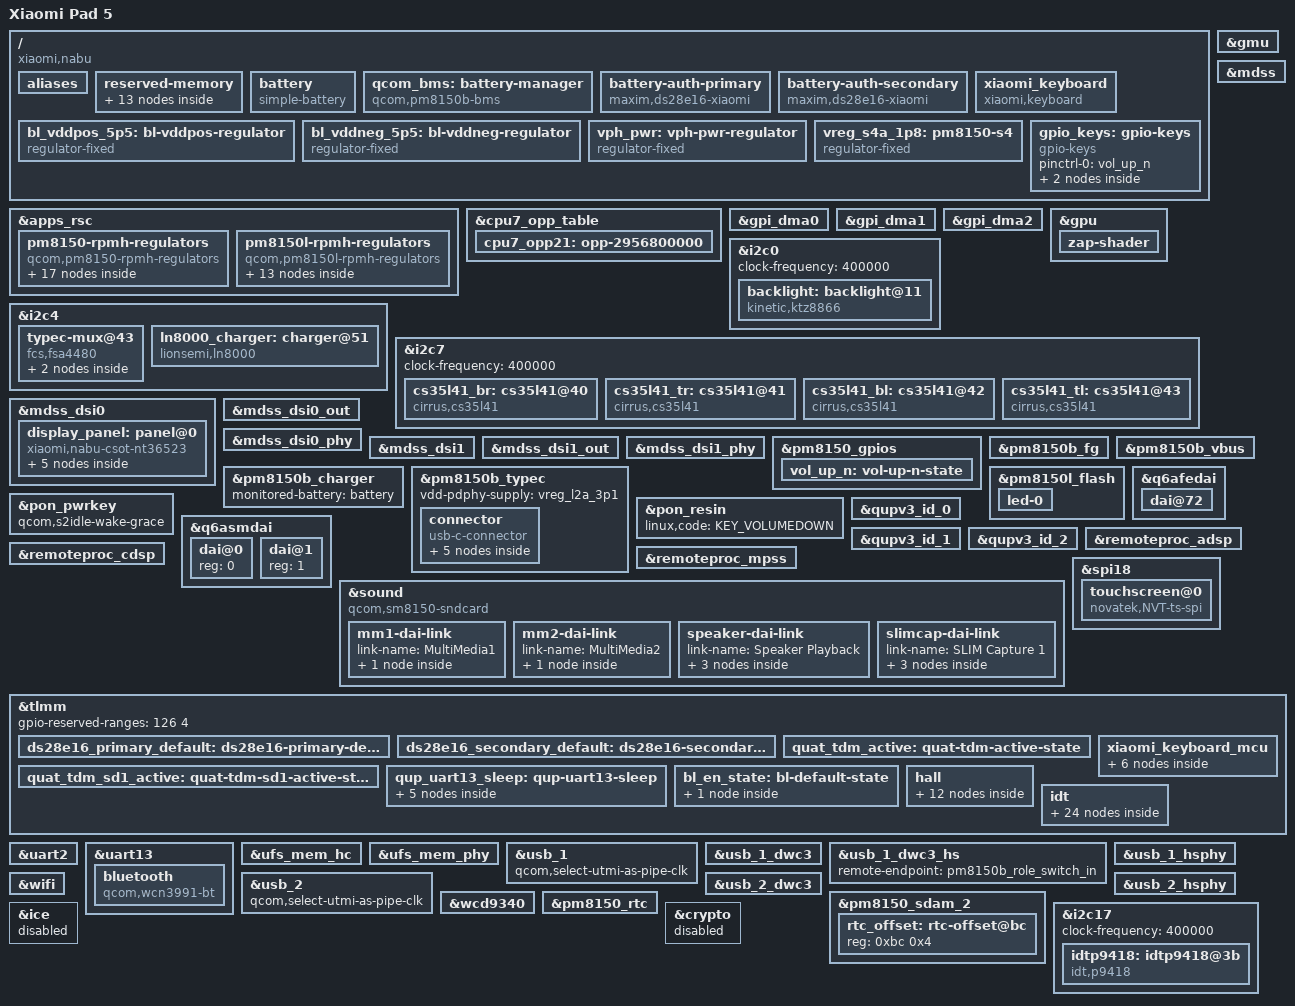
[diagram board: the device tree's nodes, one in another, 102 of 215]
// SPDX-License-Identifier: BSD-3-Clause
/*
 * Copyright (c) 2023-2024, map220v <map220v300@gmail.com>
 */

/dts-v1/;

#include <dt-bindings/arm/qcom,ids.h>
#include <dt-bindings/gpio/gpio.h>
#include <dt-bindings/leds/common.h>
#include <dt-bindings/phy/phy.h>
#include <dt-bindings/regulator/qcom,rpmh-regulator.h>
#include <dt-bindings/sound/qcom,q6asm.h>
#include <dt-bindings/usb/pd.h>
#include "sm8150.dtsi"
#include "sm8150-wcd9340.dtsi"
#include "pm8150.dtsi"
#include "pm8150b.dtsi"
#include "pm8150l.dtsi"

/delete-node/ &tz_mem;
/delete-node/ &rmtfs_mem;
/delete-node/ &adsp_mem;
/delete-node/ &mpss_mem;
/delete-node/ &venus_mem;
/delete-node/ &slpi_mem;
/delete-node/ &ipa_fw_mem;
/delete-node/ &ipa_gsi_mem;
/delete-node/ &gpu_mem;
/delete-node/ &spss_mem;
/delete-node/ &cdsp_mem;

/ {
	model = "Xiaomi Pad 5";
	compatible = "xiaomi,nabu", "qcom,sm8150";
	chassis-type = "tablet";
	qcom,msm-id = <QCOM_ID_SM8150 0x20002>; /* SM8150 v2.2 */
	qcom,board-id = <48 0>;

	aliases {
		serial0 = &uart2;
		hsuart0 = &uart13;
		wifi0 = &wifi;
	};

	reserved-memory {
		#address-cells = <2>;
		#size-cells = <2>;
		ranges;

		tz_mem: memory@86200000 {
			reg = <0x0 0x86200000 0x0 0x5500000>;
			no-map;
		};

		adsp_mem: memory@8be00000 {
			reg = <0x0 0x8be00000 0x0 0x2200000>;
			no-map;
		};

		mpss_mem: memory@8e000000 {
			reg = <0x0 0x8e000000 0x0 0x9600000>;
			no-map;
		};

		venus_mem: memory@97600000 {
			reg = <0x0 0x97600000 0x0 0x500000>;
			no-map;
		};

		slpi_mem: memory@97b00000 {
			reg = <0x0 0x97b00000 0x0 0x1400000>;
			no-map;
		};

		ipa_fw_mem: memory@98f00000 {
			reg = <0x0 0x98f00000 0x0 0x10000>;
			no-map;
		};

		ipa_gsi_mem: memory@98f10000 {
			reg = <0x0 0x98f10000 0x0 0x5000>;
			no-map;
		};

		gpu_mem: memory@98f15000 {
			reg = <0x0 0x98f15000 0x0 0x2000>;
			no-map;
		};

		spss_mem: memory@99000000 {
			reg = <0x0 0x99000000 0x0 0x100000>;
			no-map;
		};

		cdsp_mem: memory@99100000 {
			reg = <0x0 0x99100000 0x0 0x1400000>;
			no-map;
		};

		cdsp_sec_mem: memory@a8800000 {
			reg = <0x0 0xa8800000 0x0 0x3c00000>;
			no-map;
		};

		ramoops@b0000000 {
			compatible = "ramoops";
			reg = <0x0 0xb0000000 0x0 0x400000>;
			record-size = <0x1000>;
			console-size = <0x200000>;
			ecc-size = <16>;
			no-map;
		};

		rmtfs_mem: memory@fe101000 {
			compatible = "qcom,rmtfs-mem";
			reg = <0 0xfe101000 0 0x300000>;
			no-map;

			qcom,client-id = <1>;
			qcom,vmid = <15>;
		};
	};

	battery: battery {
		compatible = "simple-battery";
		charge-full-design-microamp-hours = <8720000>;
		energy-full-design-microwatt-hours = <33600000>;
		voltage-min-design-microvolt = <3400000>;
		voltage-max-design-microvolt = <4480000>;
		constant-charge-current-max-microamp = <3000000>;
		constant-charge-voltage-max-microvolt = <4480000>;
	};

	qcom_bms: battery-manager {
		compatible = "qcom,pm8150b-bms";
		qcom,required-authenticators = <3>;
		/* tcpm source psy (CC-driven attach/detach); powers direct-charge teardown */
		qcom,tcpm-psy = <&pm8150b_typec>;
		status = "okay";
	};

	battery-auth-primary {
		compatible = "maxim,ds28e16-xiaomi";
		gpios = <&tlmm 5 GPIO_ACTIVE_HIGH>;
		maxim,auth-role = "primary";
		maxim,gpio-config-address = <0x03d05000>;
		maxim,gpio-io-offset = <0x4>;
		pinctrl-names = "default";
		pinctrl-0 = <&ds28e16_primary_default>;
	};

	battery-auth-secondary {
		compatible = "maxim,ds28e16-xiaomi";
		gpios = <&tlmm 10 GPIO_ACTIVE_HIGH>;
		maxim,auth-role = "secondary";
		maxim,gpio-config-address = <0x0390a000>;
		maxim,gpio-io-offset = <0x4>;
		pinctrl-names = "default";
		pinctrl-0 = <&ds28e16_secondary_default>;
	};

	xiaomi_keyboard {
		compatible = "xiaomi,keyboard";
		pinctrl-names = "pm_kb_active", "pm_kb_suspend";
		pinctrl-0 = <&xiaomi_keyboard_active>;
		pinctrl-1 = <&xiaomi_keyboard_suspend>;
		xiaomi-keyboard,rst-gpio = <&tlmm 49 0x00>;
		xiaomi-keyboard,in-irq-gpio = <&tlmm 41 0x2001>;
		xiaomi-keyboard,vdd-gpio = <&tlmm 82 0x00>;
		status = "ok";
	};

	bl_vddpos_5p5: bl-vddpos-regulator {
		compatible = "regulator-fixed";
		regulator-name = "bl_vddpos_5p5";
		regulator-min-microvolt = <5500000>;
		regulator-max-microvolt = <5500000>;
		regulator-enable-ramp-delay = <233>;
		gpio = <&tlmm 114 GPIO_ACTIVE_HIGH>;
		enable-active-high;
		regulator-boot-on;
	};

	bl_vddneg_5p5: bl-vddneg-regulator {
		compatible = "regulator-fixed";
		regulator-name = "bl_vddneg_5p5";
		regulator-min-microvolt = <5500000>;
		regulator-max-microvolt = <5500000>;
		regulator-enable-ramp-delay = <233>;
		gpio = <&tlmm 115 GPIO_ACTIVE_HIGH>;
		enable-active-high;
		regulator-boot-on;
	};

	vph_pwr: vph-pwr-regulator {
		compatible = "regulator-fixed";
		regulator-name = "vph_pwr";
		regulator-min-microvolt = <3700000>;
		regulator-max-microvolt = <3700000>;
	};

	/*
	 * Apparently RPMh does not provide support for PM8150 S4 because it
	 * is always-on; model it as a fixed regulator.
	 */
	vreg_s4a_1p8: pm8150-s4 {
		compatible = "regulator-fixed";
		regulator-name = "vreg_s4a_1p8";

		regulator-min-microvolt = <1800000>;
		regulator-max-microvolt = <1800000>;

		regulator-always-on;
		regulator-boot-on;

		vin-supply = <&vph_pwr>;
	};

	gpio_keys: gpio-keys {
		compatible = "gpio-keys";

		pinctrl-names = "default";
		pinctrl-0 = <&vol_up_n>;

		key-vol-up {
			label = "Volume Up";
			gpios = <&pm8150_gpios 6 GPIO_ACTIVE_LOW>;
			linux,code = <KEY_VOLUMEUP>;
			debounce-interval = <15>;
			linux,can-disable;
			wakeup-source;
		};

		event-hall-sensor {
			label = "Hall Effect Sensor";
			gpios = <&tlmm 9 GPIO_ACTIVE_LOW>;
			linux,input-type = <EV_SW>;
			linux,code = <SW_LID>;
			debounce-interval = <15>;
			linux,can-disable;
			linux,notify-chain;
			wakeup-source;
		};
	};
};

&apps_rsc {
	pm8150-rpmh-regulators {
		compatible = "qcom,pm8150-rpmh-regulators";
		qcom,pmic-id = "a";

		vdd-s1-supply = <&vph_pwr>;
		vdd-s2-supply = <&vph_pwr>;
		vdd-s3-supply = <&vph_pwr>;
		vdd-s4-supply = <&vph_pwr>;
		vdd-s5-supply = <&vph_pwr>;
		vdd-s6-supply = <&vph_pwr>;
		vdd-s7-supply = <&vph_pwr>;
		vdd-s8-supply = <&vph_pwr>;
		vdd-s9-supply = <&vph_pwr>;
		vdd-s10-supply = <&vph_pwr>;

		vdd-l1-l8-l11-supply = <&vreg_s6a_0p9>;
		vdd-l2-l10-supply = <&vreg_bob>;
		vdd-l3-l4-l5-l18-supply = <&vreg_s6a_0p9>;
		vdd-l6-l9-supply = <&vreg_s8c_1p3>;
		vdd-l7-l12-l14-l15-supply = <&vreg_s5a_2p0>;
		vdd-l13-l16-l17-supply = <&vreg_bob>;

		vreg_s5a_2p0: smps5 {
			regulator-min-microvolt = <1904000>;
			regulator-max-microvolt = <2040000>;
		};

		vreg_s6a_0p9: smps6 {
			regulator-min-microvolt = <920000>;
			regulator-max-microvolt = <1128000>;
		};

		vreg_l1a_0p75: ldo1 {
			regulator-min-microvolt = <752000>;
			regulator-max-microvolt = <752000>;
			regulator-initial-mode = <RPMH_REGULATOR_MODE_HPM>;
		};

		vreg_l2a_3p1: ldo2 {
			regulator-min-microvolt = <3072000>;
			regulator-max-microvolt = <3072000>;
			regulator-initial-mode = <RPMH_REGULATOR_MODE_HPM>;
		};

		vreg_l3a_0p8: ldo3 {
			regulator-min-microvolt = <480000>;
			regulator-max-microvolt = <932000>;
			regulator-initial-mode = <RPMH_REGULATOR_MODE_HPM>;
		};

		vreg_l5a_0p8: ldo5 {
			regulator-min-microvolt = <880000>;
			regulator-max-microvolt = <880000>;
			regulator-initial-mode = <RPMH_REGULATOR_MODE_HPM>;
		};

		vreg_l6a_1p2: ldo6 {
			regulator-min-microvolt = <1200000>;
			regulator-max-microvolt = <1200000>;
			regulator-initial-mode = <RPMH_REGULATOR_MODE_HPM>;
		};

		vreg_l7a_1p8: ldo7 {
			regulator-min-microvolt = <1800000>;
			regulator-max-microvolt = <1800000>;
			regulator-initial-mode = <RPMH_REGULATOR_MODE_HPM>;
		};

		vreg_l9a_1p2: ldo9 {
			regulator-min-microvolt = <1200000>;
			regulator-max-microvolt = <1200000>;
			regulator-initial-mode = <RPMH_REGULATOR_MODE_HPM>;
		};

		vreg_l10a_2p5: ldo10 {
			regulator-min-microvolt = <2504000>;
			regulator-max-microvolt = <2950000>;
			regulator-initial-mode = <RPMH_REGULATOR_MODE_HPM>;
		};

		vreg_l11a_0p8: ldo11 {
			regulator-min-microvolt = <800000>;
			regulator-max-microvolt = <800000>;
			regulator-initial-mode = <RPMH_REGULATOR_MODE_HPM>;
		};

		vreg_l12a_1p8: ldo12 {
			regulator-min-microvolt = <1800000>;
			regulator-max-microvolt = <1800000>;
			regulator-initial-mode = <RPMH_REGULATOR_MODE_HPM>;
		};

		vreg_l13a_2p7: ldo13 {
			regulator-min-microvolt = <3000000>;
			regulator-max-microvolt = <3000000>;
			regulator-initial-mode = <RPMH_REGULATOR_MODE_HPM>;
		};

		vreg_l14a_1p8: ldo14 {
			regulator-min-microvolt = <1880000>;
			regulator-max-microvolt = <1880000>;
			regulator-initial-mode = <RPMH_REGULATOR_MODE_HPM>;
		};

		vreg_l15a_1p7: ldo15 {
			regulator-min-microvolt = <1704000>;
			regulator-max-microvolt = <1704000>;
			regulator-initial-mode = <RPMH_REGULATOR_MODE_HPM>;
		};

		vreg_l16a_2p7: ldo16 {
			regulator-min-microvolt = <2704000>;
			regulator-max-microvolt = <2960000>;
			regulator-initial-mode = <RPMH_REGULATOR_MODE_HPM>;
		};

		vreg_l17a_3p0: ldo17 {
			regulator-min-microvolt = <2856000>;
			regulator-max-microvolt = <3008000>;
			regulator-initial-mode = <RPMH_REGULATOR_MODE_HPM>;
		};
	};

	pm8150l-rpmh-regulators {
		compatible = "qcom,pm8150l-rpmh-regulators";
		qcom,pmic-id = "c";

		vdd-s1-supply = <&vph_pwr>;
		vdd-s2-supply = <&vph_pwr>;
		vdd-s3-supply = <&vph_pwr>;
		vdd-s4-supply = <&vph_pwr>;
		vdd-s5-supply = <&vph_pwr>;
		vdd-s6-supply = <&vph_pwr>;
		vdd-s7-supply = <&vph_pwr>;
		vdd-s8-supply = <&vph_pwr>;

		vdd-l1-l8-supply = <&vreg_s4a_1p8>;
		vdd-l2-l3-supply = <&vreg_s8c_1p3>;
		vdd-l4-l5-l6-supply = <&vreg_bob>;
		vdd-l7-l11-supply = <&vreg_bob>;
		vdd-l9-l10-supply = <&vreg_bob>;

		vdd-bob-supply = <&vph_pwr>;
		vdd-flash-supply = <&vreg_bob>;
		vdd-rgb-supply = <&vreg_bob>;

		vreg_bob: bob {
			regulator-min-microvolt = <3008000>;
			regulator-max-microvolt = <4000000>;
			regulator-initial-mode = <RPMH_REGULATOR_MODE_AUTO>;
			regulator-allow-bypass;
		};

		vreg_s8c_1p3: smps8 {
			regulator-min-microvolt = <1352000>;
			regulator-max-microvolt = <1352000>;
		};

		vreg_l1c_1p8: ldo1 {
			regulator-min-microvolt = <1800000>;
			regulator-max-microvolt = <1800000>;
			regulator-initial-mode = <RPMH_REGULATOR_MODE_HPM>;
		};

		vreg_l2c_1p3: ldo2 {
			regulator-min-microvolt = <1304000>;
			regulator-max-microvolt = <1304000>;
			regulator-initial-mode = <RPMH_REGULATOR_MODE_HPM>;
		};

		vreg_l3c_1p2: ldo3 {
			regulator-min-microvolt = <1200000>;
			regulator-max-microvolt = <1200000>;
			regulator-initial-mode = <RPMH_REGULATOR_MODE_HPM>;
		};

		vreg_l4c_1p8: ldo4 {
			regulator-min-microvolt = <1704000>;
			regulator-max-microvolt = <2928000>;
			regulator-initial-mode = <RPMH_REGULATOR_MODE_HPM>;
		};

		vreg_l5c_1p8: ldo5 {
			regulator-min-microvolt = <1704000>;
			regulator-max-microvolt = <2928000>;
			regulator-initial-mode = <RPMH_REGULATOR_MODE_HPM>;
		};

		vreg_l6c_2p9: ldo6 {
			regulator-min-microvolt = <1800000>;
			regulator-max-microvolt = <2960000>;
			regulator-initial-mode = <RPMH_REGULATOR_MODE_HPM>;
		};

		vreg_l7c_3p0: ldo7 {
			regulator-min-microvolt = <2856000>;
			regulator-max-microvolt = <3104000>;
			regulator-initial-mode = <RPMH_REGULATOR_MODE_HPM>;
		};

		vreg_l8c_1p8: ldo8 {
			regulator-min-microvolt = <1800000>;
			regulator-max-microvolt = <1800000>;
			regulator-initial-mode = <RPMH_REGULATOR_MODE_HPM>;
		};

		vreg_l9c_2p9: ldo9 {
			regulator-min-microvolt = <2704000>;
			regulator-max-microvolt = <2960000>;
			regulator-initial-mode = <RPMH_REGULATOR_MODE_HPM>;
		};

		vreg_l10c_3p3: ldo10 {
			regulator-min-microvolt = <3000000>;
			regulator-max-microvolt = <3312000>;
			regulator-initial-mode = <RPMH_REGULATOR_MODE_HPM>;
		};

		vreg_l11c_3p3: ldo11 {
			regulator-min-microvolt = <3104000>;
			regulator-max-microvolt = <3312000>;
			regulator-initial-mode = <RPMH_REGULATOR_MODE_HPM>;
		};
	};

	/* PM8009 is not present on these boards, even if downstream sources suggest so. */
};

//SD860 additional cpu frequency
&cpu7_opp_table {
	cpu7_opp21: opp-2956800000 {
		opp-hz = /bits/ 64 <2956800000>;
		opp-peak-kBps = <8368000 51609600>;
	};
};

&gpi_dma0 {
	status = "okay";
};

&gpi_dma1 {
	status = "okay";
};

&gpi_dma2 {
	status = "okay";
};

&gmu {
	status = "okay";
};

&gpu {
	status = "okay";

	zap-shader {
		memory-region = <&gpu_mem>;
		firmware-name = "qcom/sm8150/xiaomi/nabu/a640_zap.mbn";
	};
};

&i2c0 {
	status = "okay";
	clock-frequency = <400000>;

	backlight: backlight@11 {
		compatible = "kinetic,ktz8866";
		reg = <0x11>;
		vddpos-supply = <&bl_vddpos_5p5>;
		vddneg-supply = <&bl_vddneg_5p5>;
		enable-gpios = <&tlmm 27 GPIO_ACTIVE_HIGH>;
		current-num-sinks = <5>;
		kinetic,current-ramp-delay-ms = <128>;
		kinetic,led-enable-ramp-delay-ms = <1>;
		kinetic,enable-lcd-bias;
	};
};

&i2c4 {
	status = "okay";

	typec-mux@43 {
		compatible = "fcs,fsa4480";
		reg = <0x43>;

		vcc-supply = <&vreg_bob>;

		mode-switch;
		orientation-switch;

		port {
			fsa4480_sbu_mux: endpoint {
				remote-endpoint = <&pm8150b_sbu_mux_in>;
			};
		};
	};

	ln8000_charger: charger@51 {
		compatible = "lionsemi,ln8000";
		reg = <0x51>;

		interrupt-parent = <&tlmm>;
		interrupts = <55 IRQ_TYPE_LEVEL_LOW>;

		/* Sunwoda 8720mAh battery profile */
		lionsemi,bat-ovp-threshold-microvolt = <4560000>;
		lionsemi,bus-ovp-threshold-microvolt = <13000000>;
		lionsemi,bus-ocp-threshold-microamp = <3750000>;
		lionsemi,ntc-alarm-cfg = <226>;

		/* NTC/die monitoring handled by the PMIC fuel gauge */
		lionsemi,tbus-mon-disable;
		lionsemi,tbat-mon-disable;
		lionsemi,iin-ocp-disable;
		lionsemi,iin-reg-disable;
		lionsemi,vbat-reg-disable;
	};
};

&i2c7 {
	status = "okay";
	clock-frequency = <400000>;

	cs35l41_br: cs35l41@40 {
		compatible = "cirrus,cs35l41";
		reg = <0x40>;
		interrupt-parent = <&tlmm>;
		interrupts = <81 IRQ_TYPE_LEVEL_LOW>;
		reset-gpios = <&tlmm 92 GPIO_ACTIVE_HIGH>;
		#sound-dai-cells = <1>;
		sound-name-prefix = "BR";
		cirrus,boost-peak-milliamp = <4000>;
		cirrus,boost-ind-nanohenry = <1000>;
		cirrus,boost-cap-microfarad = <15>;
		cirrus,asp-sdout-hiz = <3>;
		cirrus,gpio2-src-select = <4>;
		cirrus,gpio2-output-enable;
	};

	cs35l41_tr: cs35l41@41 {
		compatible = "cirrus,cs35l41";
		reg = <0x41>;
		interrupt-parent = <&tlmm>;
		interrupts = <90 IRQ_TYPE_LEVEL_LOW>;
		reset-gpios = <&tlmm 92 GPIO_ACTIVE_HIGH>;
		#sound-dai-cells = <1>;
		sound-name-prefix = "TR";
		cirrus,boost-peak-milliamp = <4000>;
		cirrus,boost-ind-nanohenry = <1000>;
		cirrus,boost-cap-microfarad = <15>;
		cirrus,asp-sdout-hiz = <3>;
		cirrus,gpio2-src-select = <4>;
		cirrus,gpio2-output-enable;
	};

	cs35l41_bl: cs35l41@42 {
		compatible = "cirrus,cs35l41";
		reg = <0x42>;
		interrupt-parent = <&tlmm>;
		interrupts = <91 IRQ_TYPE_LEVEL_LOW>;
		reset-gpios = <&tlmm 92 GPIO_ACTIVE_HIGH>;
		#sound-dai-cells = <1>;
		sound-name-prefix = "BL";
		cirrus,boost-peak-milliamp = <4000>;
		cirrus,boost-ind-nanohenry = <1000>;
		cirrus,boost-cap-microfarad = <15>;
		cirrus,asp-sdout-hiz = <3>;
		cirrus,gpio2-src-select = <4>;
		cirrus,gpio2-output-enable;
	};

	cs35l41_tl: cs35l41@43 {
		compatible = "cirrus,cs35l41";
		reg = <0x43>;
		interrupt-parent = <&tlmm>;
		interrupts = <93 IRQ_TYPE_LEVEL_LOW>;
		reset-gpios = <&tlmm 92 GPIO_ACTIVE_HIGH>;
		#sound-dai-cells = <1>;
		sound-name-prefix = "TL";
		cirrus,boost-peak-milliamp = <4000>;
		cirrus,boost-ind-nanohenry = <1000>;
		cirrus,boost-cap-microfarad = <15>;
		cirrus,asp-sdout-hiz = <3>;
		cirrus,gpio2-src-select = <4>;
		cirrus,gpio2-output-enable;
	};
};

&mdss {
	status = "okay";
};

&mdss_dsi0 {
	vdda-supply = <&vreg_l3c_1p2>;
	qcom,dual-dsi-mode;
	qcom,sync-dual-dsi;
	qcom,master-dsi;
	status = "okay";

	display_panel: panel@0 {
		compatible = "xiaomi,nabu-csot-nt36523", "novatek,nt36523";
		reg = <0>;
		vddio-supply = <&vreg_l14a_1p8>;
		reset-gpios = <&tlmm 6 GPIO_ACTIVE_LOW>;
		backlight = <&backlight>;

		ports {
			#address-cells = <1>;
			#size-cells = <0>;

			port@0 {
				reg = <0>;

				panel_in_0: endpoint {
					remote-endpoint = <&mdss_dsi0_out>;
				};
			};

			port@1{
				reg = <1>;

				panel_in_1: endpoint {
					remote-endpoint = <&mdss_dsi1_out>;
				};
			};

		};
	};
};

&mdss_dsi0_out {
	data-lanes = <0 1 2>;
	remote-endpoint = <&panel_in_0>;
};

&mdss_dsi0_phy {
	vdds-supply = <&vreg_l5a_0p8>;
	phy-type = <PHY_TYPE_CPHY>;
	status = "okay";
};

&mdss_dsi1 {
	vdda-supply = <&vreg_l3c_1p2>;
	qcom,dual-dsi-mode;
	qcom,sync-dual-dsi;
	/* DSI1 is slave, so use DSI0 clocks */
	assigned-clock-parents = <&mdss_dsi0_phy 0>, <&mdss_dsi0_phy 1>;
	status = "okay";
};

&mdss_dsi1_out {
	data-lanes = <0 1 2>;
	remote-endpoint = <&panel_in_1>;
};

&mdss_dsi1_phy {
	vdds-supply = <&vreg_l5a_0p8>;
	phy-type = <PHY_TYPE_CPHY>;
	status = "okay";
};

&pm8150_gpios {
	vol_up_n: vol-up-n-state {
		pins = "gpio6";
		function = "normal";
		power-source = <1>;
		input-enable;
		bias-pull-up;
	};
};

&pm8150b_fg {
	status = "okay";
	monitored-battery = <&battery>;
	nvmem = <&pm8150_sdam_2>;
	nvmem-names = "fg_sdam";

	/* Battery profile data for Sunwoda 8720mAh battery */
	qcom,fg-profile-data = [
		 09 00 9B DB
		 1B D5 75 DA
		 68 D5 00 00
		 99 B5 42 83
		 FA 87 1E 93
		 02 8D EA 87
		 18 00 33 FC
		 E8 12 C5 04
		 50 02 CE 07
		 32 00 11 EA
		 BB E4 48 E3
		 5E 0B B5 E2
		 1D AC 12 22
		 C9 FA 3A CC
		 60 00 40 00
		 3F 00 38 00
		 2C 00 2D 00
		 3A 00 46 00
		 41 00 46 00
		 3E 00 60 00
		 44 00 3B 00
		 4B 00 47 00
		 3D 00 8C 00
		 59 64 4B 00
		 49 00 4C 08
		 60 00 4C 00
		 4F 00 6F 10
		 5E 10 57 00
		 A3 28 6B 48
		 5B 60 54 0C
		 58 00 D8 08
		 06 20 B1 14
		 6F 0B 51 FD
		 4B 1C AE 03
		 5B 05 F7 2A
		 B6 17 51 42
		 2A 5D 68 02
		 66 12 54 23
		 AD 0C DE 12
		 9D 0D F3 1C
		 21 FB 58 FD
		 50 03 FE 16
		 09 2A 76 44
		 18 5A 95 11
		 9E 24 29 DC
		 21 C3 72 C5
		 F3 1C 97 AA
		 FB 04 2D B2
		 0A 17 12 82
		 4A 84 43 8A
		 A4 90 09 80
		 48 03 13 05
		 87 02 D7 05
		 00 00 FB CD
		 78 E2 FC 07
		 17 EA 39 CD
		 1D 18 15 08
		 80 ED 35 03
		 76 05 A7 01
		 CE 07 32 00
		 9E 01 EE 05
		 5C 05 1C 03
		 D4 05 0E 02
		 BD 03 9D 02
		 C6 05 48 00
		 39 00 42 00
		 44 64 45 00
		 49 00 40 08
		 40 00 44 00
		 44 00 3B 10
		 3F 10 3F 00
		 53 28 54 48
		 57 58 62 0D
		 43 00 48 00
		 52 08 54 00
		 43 00 47 00
		 49 10 59 10
		 51 00 5F 20
		 75 40 49 58
		 56 0F 5D 00
		 4C 08 31 10
		 D8 08 FC 20
		 54 FC 6D 03
		 67 0D C7 1C
		 62 23 C5 45
		 4B 52 63 18
		 0F 02 AC 05
		 A9 03 72 12
		 3F 0A 6B 20
		 93 04 89 03
		 20 05 BE 1C
		 3C 03 C0 05
		 85 02 77 18
		 A0 03 51 04
		 9A 02 6A 00
		 35 22 4D 05
		 7A 02 EB 05
		 FB 1C AF 03
		 82 04 0B 02
		 86 18 17 03
		 59 05 23 03
		 8A 00 92 00
		 C0 00 FA 00
		 F0 21 00 00
	];

	/* KI coefficients for coulomb counter compensation */
	qcom,ki-coeff-low-chg = <315>;
	qcom,ki-coeff-med-chg = <183>;
	qcom,ki-coeff-chg-low-med-thresh-ma = <500>;
	qcom,ki-coeff-chg-med-hi-thresh-ma = <1000>;

	/* Cutoff and empty voltage parameters */
	qcom,fg-cutoff-voltage = <3400>;
	qcom,fg-cutoff-current = <200>;
	qcom,fg-empty-voltage = <3100>;
	qcom,fg-sys-term-current = <(-500)>;

	/* ESR calibration parameters */
	qcom,fg-esr-timer-chg-fast = <0 7>;
	qcom,fg-esr-timer-dischg-fast = <0 96>;
	qcom,fg-esr-timer-chg-slow = <0 96>;
	qcom,fg-esr-timer-dischg-slow = <0 96>;
	qcom,fg-esr-cal-soc-thresh = <26 230>;
	qcom,fg-esr-cal-temp-thresh = <10 40>;

	/* Capacity learning */
	qcom,cl-start-capacity = <15>;
	qcom,cl-max-increment = <5>;
	qcom,cl-max-decrement = <100>;

	/* Battery identification */
	qcom,battery-nominal-voltage-uv = <3850000>;
	qcom,battery-manufacturer = "Sunwoda";
	qcom,battery-model-name = "BN4E";
};

&pm8150b_charger {
	status = "okay";
	monitored-battery = <&battery>;
};

&pm8150b_typec {
	vdd-pdphy-supply = <&vreg_l2a_3p1>;
	status = "okay";

	connector {
		compatible = "usb-c-connector";

		power-role = "dual";
		data-role = "dual";
		self-powered;

		source-pdos = <PDO_FIXED(5000, 3000,
					 PDO_FIXED_DUAL_ROLE |
					 PDO_FIXED_USB_COMM |
					 PDO_FIXED_DATA_SWAP)>;

		sink-pdos = <PDO_FIXED(5000, 3000,
					 PDO_FIXED_DUAL_ROLE |
					 PDO_FIXED_USB_COMM |
					 PDO_FIXED_DATA_SWAP)
			     PDO_FIXED(9000, 3000,
					 PDO_FIXED_DUAL_ROLE |
					 PDO_FIXED_USB_COMM |
					 PDO_FIXED_DATA_SWAP)
			     PDO_PPS_APDO(5000, 12000, 3000)>;

		op-sink-microwatt = <33000000>;

		ports {
			#address-cells = <1>;
			#size-cells = <0>;

			port@0 {
				reg = <0>;

				pm8150b_role_switch_in: endpoint {
					remote-endpoint = <&usb_1_dwc3_hs>;
				};
			};

			port@1 {
				reg = <1>;

				pm8150b_sbu_mux_in: endpoint {
					remote-endpoint = <&fsa4480_sbu_mux>;
				};
			};
		};
	};
};

&pm8150b_vbus {
	status = "okay";
};

&pm8150l_flash {
	status = "okay";

	led-0 {
		function = LED_FUNCTION_FLASH;
		color = <LED_COLOR_ID_WHITE>;
		led-sources = <1>;
		led-max-microamp = <200000>;
		flash-max-microamp = <1000000>;
		flash-max-timeout-us = <1280000>;
	};
};

&pon_pwrkey {
	qcom,s2idle-wake-grace;
	status = "okay";
};

&pon_resin {
	linux,code = <KEY_VOLUMEDOWN>;
	status = "okay";
};

&q6afedai {
	dai@72 {
		reg = <QUATERNARY_TDM_RX_0>;
		qcom,tdm-sync-mode = <1>;
		qcom,tdm-sync-src = <1>;
		qcom,tdm-data-out = <0>;
		qcom,tdm-invert-sync = <1>;
		qcom,tdm-data-delay = <1>;
		qcom,tdm-data-align = <0>;
	};
};

&q6asmdai {
	dai@0 {
		reg = <0>;
	};

	dai@1 {
		reg = <1>;
	};
};

&qupv3_id_0 {
	status = "okay";
};

&qupv3_id_1 {
	status = "okay";
};

&qupv3_id_2 {
	status = "okay";
};

&remoteproc_adsp {
	status = "okay";
	firmware-name = "qcom/sm8150/xiaomi/nabu/adsp.mbn";
};

&remoteproc_cdsp {
	status = "okay";
	firmware-name = "qcom/sm8150/xiaomi/nabu/cdsp.mbn";
};

&remoteproc_mpss {
	status = "okay";
	firmware-name = "qcom/sm8150/xiaomi/nabu/modem.mbn";
};

&sound {
	compatible = "qcom,sm8150-sndcard";
	pinctrl-0 = <&quat_tdm_active
		&quat_tdm_sd1_active>;
	pinctrl-names = "default";
	model = "Xiaomi Pad 5";

	audio-routing =	"RX_BIAS", "MCLK",
		"AIF1 CAP", "MCLK",
		"AMIC1", "MIC BIAS3",
		"AMIC3", "MIC BIAS4",
		"MultiMedia1 Playback", "BR SPK",
		"MultiMedia1 Playback", "TR SPK",
		"MultiMedia1 Playback", "BL SPK",
		"MultiMedia1 Playback", "TL SPK";

	mm1-dai-link {
		link-name = "MultiMedia1";
		cpu {
			sound-dai = <&q6asmdai MSM_FRONTEND_DAI_MULTIMEDIA1>;
		};
	};

	mm2-dai-link {
		link-name = "MultiMedia2";
		cpu {
			sound-dai = <&q6asmdai MSM_FRONTEND_DAI_MULTIMEDIA2>;
		};
	};

	speaker-dai-link {
		link-name = "Speaker Playback";
		cpu {
			sound-dai = <&q6afedai QUATERNARY_TDM_RX_0>;
		};

		platform {
			sound-dai = <&q6routing>;
		};

		codec {
			sound-dai = <&cs35l41_br 0>, <&cs35l41_tr 0>,
				<&cs35l41_bl 0>, <&cs35l41_tl 0>;
		};
	};

	//Bottom & Top internal microphones
	slimcap-dai-link {
		link-name = "SLIM Capture 1";
		cpu {
			sound-dai = <&q6afedai SLIMBUS_0_TX>;
		};

		platform {
			sound-dai = <&q6routing>;
		};

		codec {
			sound-dai = <&wcd9340 1>; /* AIF1_CAP */
		};
	};
};

&spi18 {
	status = "okay";

	touchscreen@0 {
		compatible = "novatek,NVT-ts-spi";
		reg = <0>;

		spi-max-frequency = <9600000>;
		novatek,irq-gpio = <&tlmm 39 0x2001>;

		novatek,pen-support;
		novatek,wgp-stylus;

		/* 523 */
		novatek,swrst-n8-addr = <0x03F0FE>;
		novatek,spi-rd-fast-addr = <0x03F310>;

		firmware-name = "novatek/novatek_nt36523_fw.bin";
	};
};

&tlmm {
	gpio-reserved-ranges = <126 4>;

	ds28e16_primary_default: ds28e16-primary-default-state {
		pins = "gpio5";
		function = "gpio";
		drive-strength = <2>;
		bias-pull-up;
	};

	ds28e16_secondary_default: ds28e16-secondary-default-state {
		pins = "gpio10";
		function = "gpio";
		drive-strength = <2>;
		bias-pull-up;
	};

	quat_tdm_active: quat-tdm-active-state {
		pins = "gpio137", "gpio138";
		function = "qua_mi2s";
		drive-strength = <8>;
		bias-disable;
		output-high;
	};

	quat_tdm_sd1_active: quat-tdm-sd1-active-state {
		pins = "gpio140";
		function = "qua_mi2s";
		drive-strength = <8>;
		bias-disable;
	};

	qup_uart13_sleep: qup-uart13-sleep {
		pinmux {
			pins = "gpio43", "gpio44",
			       "gpio45", "gpio46";
			function = "gpio";
		};

		pinconf-cts {
			/*
			 * Configure a pull-down on CTS to match the pull of
			 * the Bluetooth module.
			 */
			pins = "gpio43";
			bias-pull-down;
		};

		pinconf-rts {
			/*
			 * Configure pull-down on RTS. As RTS is active low
			 * signal, pull it low to indicate the BT SoC that it
			 * can wakeup the system anytime from suspend state by
			 * pulling RX low (by sending wakeup bytes).
			 */
			 pins = "gpio44";
			 bias-pull-up;
		};

		pinconf-tx {
			/*
			 * Configure pull-up on TX when it isn't actively driven
			 * to prevent BT SoC from receiving garbage during sleep.
			 */
			pins = "gpio45";
			bias-pull-up;
		};

		pinconf-rx {
			/*
			 * Configure a pull-up on RX. This is needed to avoid
			 * garbage data when the TX pin of the Bluetooth module
			 * is floating which may cause spurious wakeups.
			 */
			pins = "gpio46";
			bias-pull-up;
		};
	};

	bl_en_state: bl-default-state {
		bl-en {
			pins = "gpio27";
			function = "gpio";

			drive-strength = <16>;
			output-high;
			bias-disable;
		};
	};

	xiaomi_keyboard_mcu {
		xiaomi_keyboard_suspend: xiaomi_keyboard_suspend {
			mux {
				pins = "gpio4";
				function = "gpio";
			};

			config {
				pins = "gpio4";
				drive-strength = <8>;
				bias-pull-down;
			};
		};

		xiaomi_keyboard_active: xiaomi_keyboard_active {
			mux {
				pins = "gpio4";
				function = "gpio";
			};

			config {
				pins = "gpio4";
				drive-strength = <8>;
				bias-pull-up;
			};
		};
	};

	hall {
		hall_intr3_active: hall_intr3_active {
			/* active state */
			mux {
				pins = "gpio101";
				function = "gpio";
			};

			config {
				pins = "gpio101";
				drive-strength = <2>; /* 2 MA */
				bias-pull-up;
				input-enable;
			};
		};

		hall_intr3_suspend: hall_intr3_suspend {
			/* sleep state */
			mux {
				pins = "gpio101";
				function = "gpio";
			};

			config {
				pins = "gpio101";
				drive-strength = <2>; /* 2 MA */
				bias-pull-up;
				input-enable;
			};
		};

		hall_intr4_active: hall_intr4_active {
			/* active state */
			mux {
				pins = "gpio134";
				function = "gpio";
			};

			config {
				pins = "gpio134";
				drive-strength = <2>; /* 2 MA */
				bias-pull-up;
				input-enable;
			};
		};

		hall_intr4_suspend: hall_intr4_suspend {
			/* sleep state */
			mux {
				pins = "gpio134";
				function = "gpio";
			};

			config {
				pins = "gpio134";
				drive-strength = <2>; /* 2 MA */
				bias-pull-up;
				input-enable;
			};
		};
	};

	idt {
		idt_int_active: idt_int_active {
			/* active state */
			mux {
				pins = "gpio95";
				function = "gpio";
			};

			config {
				pins = "gpio95";
				drive-strength = <2>; /* 2 MA */
				bias-pull-up;
				input-enable;
			};
		};

		idt_int_suspend: idt_int_suspend {
			/* sleep state */
			mux {
				pins = "gpio95";
				function = "gpio";
			};

			config {
				pins = "gpio95";
				drive-strength = <2>; /* 2 MA */
				bias-pull-up;
				input-enable;
			};
		};

		txon_enable_active: txon_enable_active {
			/* active state */
			mux {
				pins = "gpio3";
				function = "gpio";
			};

			config {
				pins = "gpio3";
				drive-strength = <16>;
				bias-disable;
				bias-pull-down;
				output-low;
			};
		};

		txon_enable_suspend: txon_enable_suspend {
			/* sleep state */
			mux {
				pins = "gpio3";
				function = "gpio";
			};

			config {
				pins = "gpio3";
				drive-strength = <16>;
				bias-disable;
				bias-pull-down;
				output-low;
			};
		};

		power_good_active: power_good_active {
			/* active state */
			mux {
				pins = "gpio94";
				function = "gpio";
			};
			config {
				pins = "gpio94";
				drive-strength = <2>; /* 2 MA */
				bias-pull-down;
				input-enable;
				};

		};

		power_good_suspend: power_good_suspend {
			/* active state */
			mux {
				pins = "gpio94";
				function = "gpio";
			};
			config {
				pins = "gpio94";
				drive-strength = <2>; /* 2 MA */
				bias-pull-up;
				input-enable;
				};
		};

		reverse_booset_enable_active: reverse_booset_enable__active {
			/* active state */
			mux {
				pins = "gpio47";
				function = "gpio";
			};

			config {
				pins = "gpio47";
				drive-strength = <16>;
				bias-pull-down;
				output-low;
			};
		};

		reverse_booset_enable_suspend: reverse_booset_enable_suspend {
			/* sleep state */
			mux {
				pins = "gpio47";
				function = "gpio";
			};

			config {
				pins = "gpio47";
				drive-strength = <16>;
				bias-pull-down;
				output-low;
			};
		};
	};
};

&uart2 {
	status = "okay";
};

&uart13 {
	status = "okay";

	/delete-property/interrupts;
	interrupts-extended = <&intc GIC_SPI 585 IRQ_TYPE_LEVEL_HIGH>,
				<&tlmm 46 IRQ_TYPE_EDGE_FALLING>;

	pinctrl-names = "default", "sleep";
	pinctrl-1 = <&qup_uart13_sleep>;

	bluetooth: bluetooth {
		compatible = "qcom,wcn3991-bt";
		vddio-supply = <&vreg_l1a_0p75>;
		vddxo-supply = <&vreg_l7a_1p8>;
		vddrf-supply = <&vreg_l2c_1p3>;
		vddch0-supply = <&vreg_l11c_3p3>;
		max-speed = <3200000>;
		local-bd-address = [ 21 00 00 00 5a ad ];
	};
};

&ufs_mem_hc {
	status = "okay";

	vcc-supply = <&vreg_l10a_2p5>;
	vcc-max-microamp = <750000>;
	vccq-supply = <&vreg_l9a_1p2>;
	vccq-max-microamp = <700000>;
	vccq2-supply = <&vreg_s4a_1p8>;
	vccq2-max-microamp = <750000>;

	/delete-property/ resets;
	/delete-property/ reset-names;
	freq-table-hz =
		<37500000 300000000>,
		<0 0>,
		<0 0>,
		<37500000 300000000>,
		<37500000 300000000>,
		<0 0>,
		<0 0>,
		<0 0>;
};

&ufs_mem_phy {
	status = "okay";

	vdda-phy-supply = <&vreg_l5a_0p8>;
	vdda-phy-max-microamp = <90200>;
	vdda-pll-supply = <&vreg_l3c_1p2>;
	vdda-pll-max-microamp = <19000>;
};

&usb_1 {
	/* USB 2.0 only */
	qcom,select-utmi-as-pipe-clk;
	status = "okay";
};

&usb_1_dwc3 {
	dr_mode = "otg";
	maximum-speed = "high-speed";
	/* Remove USB3 phy */
	phys = <&usb_1_hsphy>;
	phy-names = "usb2-phy";
	usb-role-switch;
};

&usb_1_dwc3_hs {
	remote-endpoint = <&pm8150b_role_switch_in>;
};

&usb_1_hsphy {
	vdda-pll-supply = <&vreg_l5a_0p8>;
	vdda18-supply = <&vreg_l12a_1p8>;
	vdda33-supply = <&vreg_l2a_3p1>;
	status = "okay";
};

&usb_2 {
	/* USB 2.0 only */
	qcom,select-utmi-as-pipe-clk;
	status = "okay";
};

&usb_2_hsphy {
	vdda-pll-supply = <&vreg_l5a_0p8>;
	vdda18-supply = <&vreg_l12a_1p8>;
	vdda33-supply = <&vreg_l2a_3p1>;
	status = "okay";
};

&usb_2_dwc3 {
	dr_mode = "host";
	maximum-speed = "high-speed";
	/* Remove USB3 phy */
	phys = <&usb_2_hsphy>;
	phy-names = "usb2-phy";
};

&wcd9340 {
	reset-gpios = <&tlmm 143 GPIO_ACTIVE_HIGH>;
	vdd-buck-sido-supply = <&vreg_s4a_1p8>;
	vdd-buck-supply = <&vreg_s4a_1p8>;
	vdd-tx-supply = <&vreg_s4a_1p8>;
	vdd-rx-supply = <&vreg_s4a_1p8>;
	vdd-io-supply = <&vreg_s4a_1p8>;

	qcom,micbias1-microvolt = <1800000>;
	qcom,micbias2-microvolt = <2750000>;
	qcom,micbias3-microvolt = <1800000>;
	qcom,micbias4-microvolt = <1800000>;

	qcom,hphl-jack-type-normally-open;
	qcom,ground-jack-type-normally-open;
	qcom,mbhc-buttons-vthreshold-microvolt = <75000 150000 237000 500000 500000 500000 500000 500000>;
	qcom,mbhc-headset-vthreshold-microvolt = <2600000>;
	qcom,mbhc-headphone-vthreshold-microvolt = <50000>;
};

&wifi {
	status = "okay";

	vdd-0.8-cx-mx-supply = <&vreg_l1a_0p75>;
	vdd-1.8-xo-supply = <&vreg_l7a_1p8>;
	vdd-1.3-rfa-supply = <&vreg_l2c_1p3>;
	vdd-3.3-ch0-supply = <&vreg_l11c_3p3>;
};

&pm8150_rtc {
       nvmem-cells = <&rtc_offset>;
       nvmem-cell-names = "offset";
       status = "okay";
};

&pm8150_sdam_2 {
       status = "okay";
       rtc_offset: rtc-offset@bc {
               reg = <0xbc 0x4>;
       };
};

&i2c17 {
	status = "okay";
	clock-frequency = <400000>;
	idtp9418: idtp9418@3b {
		compatible = "idt,p9418";
		status = "ok";
		reg = <0x3b>;
		idt,irq-gpios = <&tlmm 95 GPIO_ACTIVE_HIGH>;
		idt,hall3-gpios = <&tlmm 101 GPIO_ACTIVE_HIGH>;
		idt,hall4-gpios = <&tlmm 134 GPIO_ACTIVE_HIGH>;
		idt,reverse-enable-gpios = <&tlmm 3 GPIO_ACTIVE_HIGH>;
		idt,reverse-boost-enable-gpios = <&tlmm 47 GPIO_ACTIVE_HIGH>;
		pinctrl-names = "idt_active", "idt_suspend";
		pinctrl-0 = <&idt_int_active &hall_intr3_active &hall_intr4_active 
				&txon_enable_active &power_good_active 
				&reverse_booset_enable_active>;
		pinctrl-1 = <&idt_int_suspend &hall_intr3_suspend &hall_intr4_suspend 
				&txon_enable_suspend &power_good_suspend 
				&reverse_booset_enable_suspend>;
	};
};

#include "sm8150-xiaomi-nabu-camera.dtsi"
#include "sm8150-xiaomi-nabu-iris.dtsi"
#include "sm8150-xiaomi-nabu-sensors.dtsi"

&crypto {
	status = "disabled";
};

&ufs_mem_hc {
	/delete-property/ qcom,ice;
};

&ice {
	status = "disabled";
};
